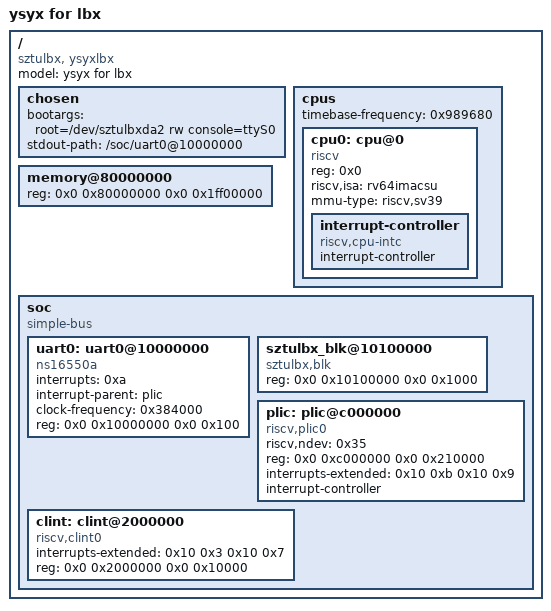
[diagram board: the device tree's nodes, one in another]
/dts-v1/;

/ {
	#address-cells = <0x2>;
	#size-cells = <0x2>;
	compatible = "sztulbx, ysyxlbx";
	model = "ysyx for lbx";

	chosen {
        bootargs = "root=/dev/sztulbxda2 rw console=ttyS0";
		stdout-path = "/soc/uart0@10000000";
	};

	memory@80000000 {
		device_type = "memory";
		reg = <0x0 0x80000000 0x0 0x1ff00000>;
	};

	cpus {
		#address-cells = <0x1>;
		#size-cells = <0x0>;
		timebase-frequency = <0x989680>;

		cpu0: cpu@0 {
			device_type = "cpu";
			reg = <0x0>;
			status = "okay";
			compatible = "riscv";
			riscv,isa = "rv64imacsu";
			mmu-type = "riscv,sv39";

			interrupt-controller {
				#interrupt-cells = <0x1>;
				interrupt-controller;
				compatible = "riscv,cpu-intc";
                phandle = <0x10>;
			};
		};
	};

	soc {
		#address-cells = <0x2>;
		#size-cells = <0x2>;
		compatible = "simple-bus";
		ranges;

		uart0: uart0@10000000 {
			interrupts = <0xa>;
			interrupt-parent = <&plic>;
			clock-frequency = <0x384000>;
			reg = <0x0 0x10000000 0x0 0x100>;
			compatible = "ns16550a";
		};

        sztulbx_blk@10100000 {
			reg = <0x0 0x10100000 0x0 0x1000>;
			compatible = "sztulbx,blk";
		};

		plic: plic@c000000 {
			riscv,ndev = <0x35>;
			reg = <0x0 0xc000000 0x0 0x210000>;
			interrupts-extended = <0x10 0xb 0x10 0x9>;
			interrupt-controller;
			compatible = "riscv,plic0";
			#interrupt-cells = <0x1>;
			#address-cells = <0x0>;
		};

		clint: clint@2000000 {
			interrupts-extended = <0x10 0x3 0x10 0x7>;
			reg = <0x0 0x2000000 0x0 0x10000>;
			compatible = "riscv,clint0";
		};
	};
};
